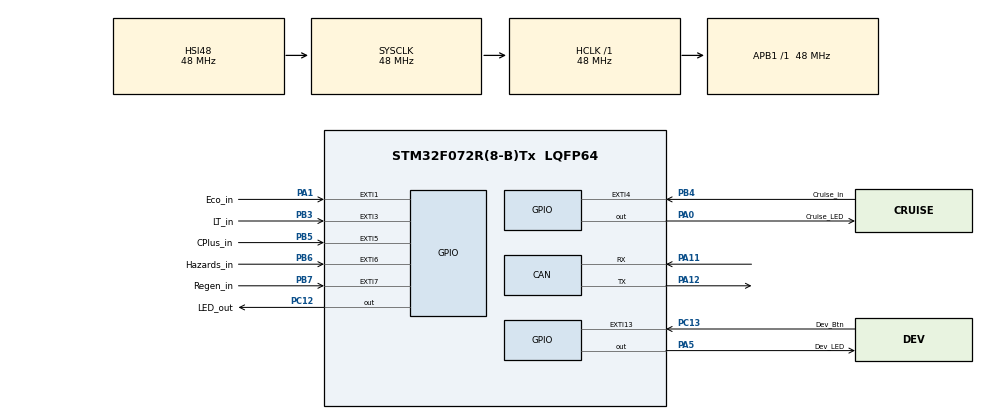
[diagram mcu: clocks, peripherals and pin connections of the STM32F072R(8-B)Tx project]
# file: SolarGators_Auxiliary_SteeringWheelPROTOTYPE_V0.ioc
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CAN.CalculateTimeQuantum=333.3333333333333
Mcu.Family=STM32F0
Mcu.Name=STM32F072R(8-B)Tx
Mcu.Package=LQFP64
NVIC.EXTI4_15_IRQn=true\:0\:0\:false\:false\:true\:true\:true
PA0.GPIO_Label=Cruise_LED
PA0.GPIO_Speed=GPIO_SPEED_FREQ_HIGH
PA0.Signal=GPIO_Output
PA1.GPIO_Label=Eco_in
PA1.Signal=GPXTI1
PA11.Mode=Master
PA11.Signal=CAN_RX
PA12.Mode=Master
PA12.Signal=CAN_TX
PA13.Mode=Serial_Wire
PA13.Signal=SYS_SWDIO
PA14.Mode=Serial_Wire
PA14.Signal=SYS_SWCLK
PA5.GPIO_Label=Dev_LED
PA5.PinState=GPIO_PIN_SET
PA5.Signal=GPIO_Output
PB3.GPIO_Label=LT_in
PB3.Signal=GPXTI3
PB4.GPIO_Label=Cruise_in
PB4.Signal=GPXTI4
PB5.GPIO_Label=CPlus_in
PB5.Signal=GPXTI5
PB6.GPIO_Label=Hazards_in
PB6.Signal=GPXTI6
PB7.GPIO_Label=Regen_in
PB7.Signal=GPXTI7
PC12.GPIO_Label=LED_out
PC12.Signal=GPIO_Output
PC13.GPIO_Label=Dev_Btn
PC13.Signal=GPXTI13
ProjectManager.HeapSize=0x200
ProjectManager.StackSize=0x400
ProjectManager.TargetToolchain=STM32CubeIDE
RCC.AHBFreq_Value=48000000
RCC.APB1Freq_Value=48000000
RCC.APB1TimFreq_Value=48000000
RCC.HCLKFreq_Value=48000000
RCC.PLLSourceVirtual=RCC_PLLSOURCE_HSI48
RCC.SYSCLKFreq_VALUE=48000000
RCC.SYSCLKSource=RCC_SYSCLKSOURCE_HSI48
TIM6.Period=750
TIM6.Prescaler=32000
VP_TIM6_VS_ClockSourceINT.Mode=Enable_Timer
board=custom

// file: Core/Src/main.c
/* USER CODE BEGIN Header */
///**
//  ******************************************************************************
//  * @file           : main.c
//  * @brief          : Main program body
//  ******************************************************************************
//  * @attention
//  *
//  * <h2><center>&copy; Copyright (c) 2020 STMicroelectronics.
//  * All rights reserved.</center></h2>
//  *
//  * This software component is licensed by ST under BSD 3-Clause license,
//  * the "License"; You may not use this file except in compliance with the
//  * License. You may obtain a copy of the License at:
//  *                        opensource.org/licenses/BSD-3-Clause
//  *
//  ******************************************************************************
//  */
/* USER CODE END Header */

#include "main.h"

/* USER CODE BEGIN Includes */
//
/* USER CODE END Includes */

/* USER CODE BEGIN PTD */
//
/* USER CODE END PTD */

/* USER CODE BEGIN PM */
//
/* USER CODE END PM */

CAN_HandleTypeDef hcan;

TIM_HandleTypeDef htim6;

/* USER CODE BEGIN PV */
//
/* USER CODE END PV */

void SystemClock_Config(void);
static void MX_GPIO_Init(void);
static void MX_TIM6_Init(void);
static void MX_CAN_Init(void);
/* USER CODE BEGIN PFP */
//
/* USER CODE END PFP */

/* USER CODE BEGIN 0 */
//
/* USER CODE END 0 */

int main(void)
{
  /* USER CODE BEGIN 1 */
//
  /* USER CODE END 1 */

  /* MCU Configuration--------------------------------------------------------*/

  /* Reset of all peripherals, Initializes the Flash interface and the Systick. */
  HAL_Init();

  /* USER CODE BEGIN Init */
//
  /* USER CODE END Init */

  /* Configure the system clock */
  SystemClock_Config();

  /* USER CODE BEGIN SysInit */
//
  /* USER CODE END SysInit */

  /* Initialize all configured peripherals */
  MX_GPIO_Init();
  MX_TIM6_Init();
  MX_CAN_Init();
  /* USER CODE BEGIN 2 */
//
  /* USER CODE END 2 */

  /* Infinite loop */
  /* USER CODE BEGIN WHILE */
//  while (1)
//  {
    /* USER CODE END WHILE */

    /* USER CODE BEGIN 3 */
//  }
  /* USER CODE END 3 */
}

void SystemClock_Config(void)
{
  RCC_OscInitTypeDef RCC_OscInitStruct = {0};
  RCC_ClkInitTypeDef RCC_ClkInitStruct = {0};

  /** Initializes the CPU, AHB and APB busses clocks
  */
  RCC_OscInitStruct.OscillatorType = RCC_OSCILLATORTYPE_HSI48;
  RCC_OscInitStruct.HSI48State = RCC_HSI48_ON;
  RCC_OscInitStruct.PLL.PLLState = RCC_PLL_NONE;
  if (HAL_RCC_OscConfig(&RCC_OscInitStruct) != HAL_OK)
  {
    Error_Handler();
  }
  /** Initializes the CPU, AHB and APB busses clocks
  */
  RCC_ClkInitStruct.ClockType = RCC_CLOCKTYPE_HCLK|RCC_CLOCKTYPE_SYSCLK
                              |RCC_CLOCKTYPE_PCLK1;
  RCC_ClkInitStruct.SYSCLKSource = RCC_SYSCLKSOURCE_HSI48;
  RCC_ClkInitStruct.AHBCLKDivider = RCC_SYSCLK_DIV1;
  RCC_ClkInitStruct.APB1CLKDivider = RCC_HCLK_DIV1;

  if (HAL_RCC_ClockConfig(&RCC_ClkInitStruct, FLASH_LATENCY_1) != HAL_OK)
  {
    Error_Handler();
  }
}

static void MX_CAN_Init(void)
{

  hcan.Instance = CAN;
  hcan.Init.Prescaler = 16;
  hcan.Init.Mode = CAN_MODE_NORMAL;
  hcan.Init.SyncJumpWidth = CAN_SJW_1TQ;
  hcan.Init.TimeSeg1 = CAN_BS1_1TQ;
  hcan.Init.TimeSeg2 = CAN_BS2_1TQ;
  hcan.Init.TimeTriggeredMode = DISABLE;
  hcan.Init.AutoBusOff = DISABLE;
  hcan.Init.AutoWakeUp = DISABLE;
  hcan.Init.AutoRetransmission = DISABLE;
  hcan.Init.ReceiveFifoLocked = DISABLE;
  hcan.Init.TransmitFifoPriority = DISABLE;
  if (HAL_CAN_Init(&hcan) != HAL_OK)
  {
    Error_Handler();
  }

}

static void MX_TIM6_Init(void)
{

  /* USER CODE BEGIN TIM6_Init 0 */
//
  /* USER CODE END TIM6_Init 0 */

  TIM_MasterConfigTypeDef sMasterConfig = {0};

  /* USER CODE BEGIN TIM6_Init 1 */
//
  /* USER CODE END TIM6_Init 1 */
  htim6.Instance = TIM6;
  htim6.Init.Prescaler = 32000;
  htim6.Init.CounterMode = TIM_COUNTERMODE_UP;
  htim6.Init.Period = 750;
  htim6.Init.AutoReloadPreload = TIM_AUTORELOAD_PRELOAD_DISABLE;
  if (HAL_TIM_Base_Init(&htim6) != HAL_OK)
  {
    Error_Handler();
  }
  sMasterConfig.MasterOutputTrigger = TIM_TRGO_RESET;
  sMasterConfig.MasterSlaveMode = TIM_MASTERSLAVEMODE_DISABLE;
  if (HAL_TIMEx_MasterConfigSynchronization(&htim6, &sMasterConfig) != HAL_OK)
  {
    Error_Handler();
  }
  /* USER CODE BEGIN TIM6_Init 2 */
//
  /* USER CODE END TIM6_Init 2 */

}

static void MX_GPIO_Init(void)
{
  GPIO_InitTypeDef GPIO_InitStruct = {0};

  /* GPIO Ports Clock Enable */
  __HAL_RCC_GPIOC_CLK_ENABLE();
  __HAL_RCC_GPIOA_CLK_ENABLE();
  __HAL_RCC_GPIOB_CLK_ENABLE();

  /*Configure GPIO pin Output Level */
  HAL_GPIO_WritePin(Cruise_LED_GPIO_Port, Cruise_LED_Pin, GPIO_PIN_RESET);

  /*Configure GPIO pin Output Level */
  HAL_GPIO_WritePin(Dev_LED_GPIO_Port, Dev_LED_Pin, GPIO_PIN_SET);

  /*Configure GPIO pin Output Level */
  HAL_GPIO_WritePin(LED_out_GPIO_Port, LED_out_Pin, GPIO_PIN_RESET);

  /*Configure GPIO pin : Dev_Btn_Pin */
  GPIO_InitStruct.Pin = Dev_Btn_Pin;
  GPIO_InitStruct.Mode = GPIO_MODE_IT_RISING;
  GPIO_InitStruct.Pull = GPIO_NOPULL;
  HAL_GPIO_Init(Dev_Btn_GPIO_Port, &GPIO_InitStruct);

  /*Configure GPIO pin : Cruise_LED_Pin */
  GPIO_InitStruct.Pin = Cruise_LED_Pin;
  GPIO_InitStruct.Mode = GPIO_MODE_OUTPUT_PP;
  GPIO_InitStruct.Pull = GPIO_NOPULL;
  GPIO_InitStruct.Speed = GPIO_SPEED_FREQ_HIGH;
  HAL_GPIO_Init(Cruise_LED_GPIO_Port, &GPIO_InitStruct);

  /*Configure GPIO pin : Eco_in_Pin */
  GPIO_InitStruct.Pin = Eco_in_Pin;
  GPIO_InitStruct.Mode = GPIO_MODE_IT_RISING;
  GPIO_InitStruct.Pull = GPIO_NOPULL;
  HAL_GPIO_Init(Eco_in_GPIO_Port, &GPIO_InitStruct);

  /*Configure GPIO pin : Dev_LED_Pin */
  GPIO_InitStruct.Pin = Dev_LED_Pin;
  GPIO_InitStruct.Mode = GPIO_MODE_OUTPUT_PP;
  GPIO_InitStruct.Pull = GPIO_NOPULL;
  GPIO_InitStruct.Speed = GPIO_SPEED_FREQ_LOW;
  HAL_GPIO_Init(Dev_LED_GPIO_Port, &GPIO_InitStruct);

  /*Configure GPIO pin : LED_out_Pin */
  GPIO_InitStruct.Pin = LED_out_Pin;
  GPIO_InitStruct.Mode = GPIO_MODE_OUTPUT_PP;
  GPIO_InitStruct.Pull = GPIO_NOPULL;
  GPIO_InitStruct.Speed = GPIO_SPEED_FREQ_LOW;
  HAL_GPIO_Init(LED_out_GPIO_Port, &GPIO_InitStruct);

  /*Configure GPIO pins : LT_in_Pin Cruise_in_Pin CPlus_in_Pin Hazards_in_Pin
                           Regen_in_Pin */
  GPIO_InitStruct.Pin = LT_in_Pin|Cruise_in_Pin|CPlus_in_Pin|Hazards_in_Pin
                          |Regen_in_Pin;
  GPIO_InitStruct.Mode = GPIO_MODE_IT_RISING;
  GPIO_InitStruct.Pull = GPIO_NOPULL;
  HAL_GPIO_Init(GPIOB, &GPIO_InitStruct);

  /* EXTI interrupt init*/
  HAL_NVIC_SetPriority(EXTI4_15_IRQn, 0, 0);
  HAL_NVIC_EnableIRQ(EXTI4_15_IRQn);

}

/* USER CODE BEGIN 4 */
//
/* USER CODE END 4 */

void Error_Handler(void)
{
  /* USER CODE BEGIN Error_Handler_Debug */
//  /* User can add his own implementation to report the HAL error return state */
//
  /* USER CODE END Error_Handler_Debug */
}

#ifdef  USE_FULL_ASSERT
/**
  * @brief  Reports the name of the source file and the source line number
  *         where the assert_param error has occurred.
  * @param  file: pointer to the source file name
  * @param  line: assert_param error line source number
  * @retval None
  */
void assert_failed(char *file, uint32_t line)
{
  /* USER CODE BEGIN 6 */
//  /* User can add his own implementation to report the file name and line number,
//     tex: printf("Wrong parameters value: file %s on line %d\r\n", file, line) */
  /* USER CODE END 6 */
}
#endif /* USE_FULL_ASSERT */

/************************ (C) COPYRIGHT STMicroelectronics *****END OF FILE****/
